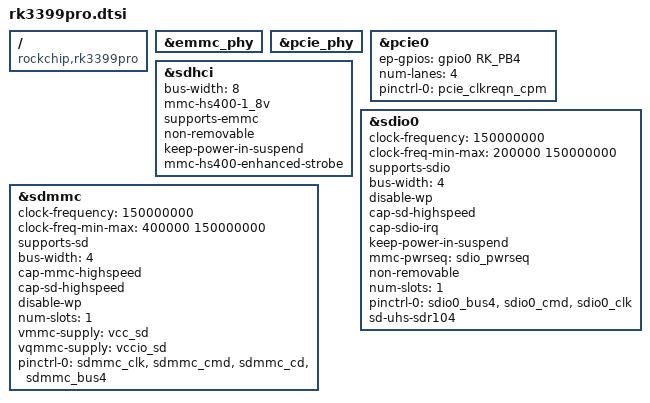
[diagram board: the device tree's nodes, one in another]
// SPDX-License-Identifier: (GPL-2.0+ OR MIT)
// Copyright (c) 2019 Fuzhou Rockchip Electronics Co., Ltd.

#include "rk3399.dtsi"

/ {
	compatible = "rockchip,rk3399pro";
};

&emmc_phy {
	status = "okay";
};

/* Default to enabled since AP talk to NPU part over pcie */
&pcie_phy {
	status = "okay";
};

/* Default to enabled since AP talk to NPU part over pcie */
&pcie0 {
	ep-gpios = <&gpio0 RK_PB4 GPIO_ACTIVE_HIGH>;
	num-lanes = <4>;
	pinctrl-names = "default";
	pinctrl-0 = <&pcie_clkreqn_cpm>;
	status = "okay";
};

&sdhci {
	bus-width = <8>;
	mmc-hs400-1_8v;
	supports-emmc;
	non-removable;
	keep-power-in-suspend;
	mmc-hs400-enhanced-strobe;
	status = "okay";
};

&sdio0 {
	clock-frequency = <150000000>;
	clock-freq-min-max = <200000 150000000>;
	supports-sdio;
	bus-width = <4>;
	disable-wp;
	cap-sd-highspeed;
	cap-sdio-irq;
	keep-power-in-suspend;
	mmc-pwrseq = <&sdio_pwrseq>;
	non-removable;
	num-slots = <1>;
	pinctrl-names = "default";
	pinctrl-0 = <&sdio0_bus4 &sdio0_cmd &sdio0_clk>;
	sd-uhs-sdr104;
	status = "okay";
};

&sdmmc {
	clock-frequency = <150000000>;
	clock-freq-min-max = <400000 150000000>;
	supports-sd;
	bus-width = <4>;
	cap-mmc-highspeed;
	cap-sd-highspeed;
	disable-wp;
	num-slots = <1>;
	vmmc-supply = <&vcc_sd>;
	vqmmc-supply = <&vccio_sd>;
	pinctrl-names = "default";
	pinctrl-0 = <&sdmmc_clk &sdmmc_cmd &sdmmc_cd &sdmmc_bus4>;
	status = "okay";
};
